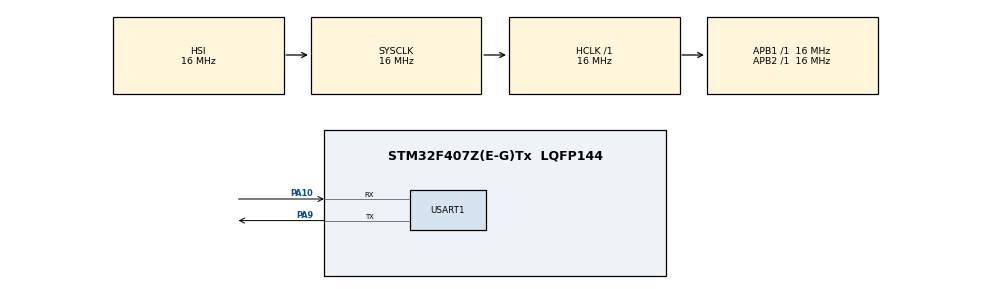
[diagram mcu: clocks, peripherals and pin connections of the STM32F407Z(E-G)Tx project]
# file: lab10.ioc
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Mcu.Family=STM32F4
Mcu.Name=STM32F407Z(E-G)Tx
Mcu.Package=LQFP144
NVIC.PriorityGroup=NVIC_PRIORITYGROUP_4
PA10.Mode=Asynchronous
PA10.Signal=USART1_RX
PA9.Mode=Asynchronous
PA9.Signal=USART1_TX
ProjectManager.HeapSize=0x200
ProjectManager.StackSize=0x400
ProjectManager.TargetToolchain=STM32CubeIDE
RCC.AHBFreq_Value=16000000
RCC.APB1Freq_Value=16000000
RCC.APB2Freq_Value=16000000
RCC.CortexFreq_Value=16000000
RCC.HSE_VALUE=25000000
RCC.HSI_VALUE=16000000
RCC.LSE_VALUE=32768
RCC.SYSCLKFreq_VALUE=16000000
RCC.VCOOutputFreq_Value=192000000
USART1.VirtualMode=VM_ASYNC
board=custom

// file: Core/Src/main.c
/* USER CODE BEGIN Header */
/**
  ******************************************************************************
  * @file           : main.c
  * @brief          : Main program body
  ******************************************************************************
  * @attention
  *
  * <h2><center>&copy; Copyright (c) 2022 STMicroelectronics.
  * All rights reserved.</center></h2>
  *
  * This software component is licensed by ST under BSD 3-Clause license,
  * the "License"; You may not use this file except in compliance with the
  * License. You may obtain a copy of the License at:
  *                        opensource.org/licenses/BSD-3-Clause
  *
  ******************************************************************************
  */
/* USER CODE END Header */
#include "main.h"

/* USER CODE BEGIN Includes */
#include "string.h"
#include "stdio.h"
/* USER CODE END Includes */

UART_HandleTypeDef huart1;

/* USER CODE BEGIN PV */
uint32_t SIZE_ONE_SECTOR = 0x4000;		// 16KB
uint32_t ADDR_FLASH_SECTOR = 0x0800C000; 	// address of 3rd sector
uint32_t val_000 = 0x01234567;
/* USER CODE END PV */

void SystemClock_Config(void);
static void MX_GPIO_Init(void);
static void MX_USART1_UART_Init(void);
/* USER CODE BEGIN PFP */
void flash_erase_one_sector(uint8_t flash_sector);
void flash_write_uint32(uint32_t, uint32_t);
uint32_t flash_read_uint32(uint32_t);
/* USER CODE END PFP */

int main(void)
{

  /* MCU Configuration--------------------------------------------------------*/

  /* Reset of all peripherals, Initializes the Flash interface and the Systick. */
  HAL_Init();

  /* USER CODE BEGIN Init */
  HAL_Delay(2000);
  /* USER CODE END Init */

  /* Configure the system clock */
  SystemClock_Config();

  /* Initialize all configured peripherals */
  MX_GPIO_Init();
  MX_USART1_UART_Init();
  /* USER CODE BEGIN 2 */
  flash_erase_one_sector(FLASH_SECTOR_3);
  flash_write_uint32(ADDR_FLASH_SECTOR, val_000);
  /* USER CODE END 2 */

  /* Infinite loop */
  while (1)
  {

  }
}

void SystemClock_Config(void)
{
  RCC_OscInitTypeDef RCC_OscInitStruct = {0};
  RCC_ClkInitTypeDef RCC_ClkInitStruct = {0};

  /** Configure the main internal regulator output voltage
  */
  __HAL_RCC_PWR_CLK_ENABLE();
  __HAL_PWR_VOLTAGESCALING_CONFIG(PWR_REGULATOR_VOLTAGE_SCALE1);
  /** Initializes the RCC Oscillators according to the specified parameters
  * in the RCC_OscInitTypeDef structure.
  */
  RCC_OscInitStruct.OscillatorType = RCC_OSCILLATORTYPE_HSI;
  RCC_OscInitStruct.HSIState = RCC_HSI_ON;
  RCC_OscInitStruct.HSICalibrationValue = RCC_HSICALIBRATION_DEFAULT;
  RCC_OscInitStruct.PLL.PLLState = RCC_PLL_NONE;
  if (HAL_RCC_OscConfig(&RCC_OscInitStruct) != HAL_OK)
  {
    Error_Handler();
  }
  /** Initializes the CPU, AHB and APB buses clocks
  */
  RCC_ClkInitStruct.ClockType = RCC_CLOCKTYPE_HCLK|RCC_CLOCKTYPE_SYSCLK
                              |RCC_CLOCKTYPE_PCLK1|RCC_CLOCKTYPE_PCLK2;
  RCC_ClkInitStruct.SYSCLKSource = RCC_SYSCLKSOURCE_HSI;
  RCC_ClkInitStruct.AHBCLKDivider = RCC_SYSCLK_DIV1;
  RCC_ClkInitStruct.APB1CLKDivider = RCC_HCLK_DIV1;
  RCC_ClkInitStruct.APB2CLKDivider = RCC_HCLK_DIV1;

  if (HAL_RCC_ClockConfig(&RCC_ClkInitStruct, FLASH_LATENCY_0) != HAL_OK)
  {
    Error_Handler();
  }
}

static void MX_USART1_UART_Init(void)
{

  huart1.Instance = USART1;
  huart1.Init.BaudRate = 115200;
  huart1.Init.WordLength = UART_WORDLENGTH_8B;
  huart1.Init.StopBits = UART_STOPBITS_1;
  huart1.Init.Parity = UART_PARITY_NONE;
  huart1.Init.Mode = UART_MODE_TX_RX;
  huart1.Init.HwFlowCtl = UART_HWCONTROL_NONE;
  huart1.Init.OverSampling = UART_OVERSAMPLING_16;
  if (HAL_UART_Init(&huart1) != HAL_OK)
  {
    Error_Handler();
  }

}

static void MX_GPIO_Init(void)
{

  /* GPIO Ports Clock Enable */
  __HAL_RCC_GPIOA_CLK_ENABLE();

}

/* USER CODE BEGIN 4 */
void flash_erase_one_sector(uint8_t flash_sector)
{
	FLASH_EraseInitTypeDef EraseInitStruct; // структура для очищення флеша

	EraseInitStruct.TypeErase = FLASH_TYPEERASE_SECTORS;
	EraseInitStruct.Banks = FLASH_BANK_1;
	EraseInitStruct.Sector = flash_sector;
	EraseInitStruct.NbSectors = 1;
	EraseInitStruct.VoltageRange = FLASH_VOLTAGE_RANGE_3;

	uint32_t sector_error = 0; // змінна в яку запишеться адреса сторінки, при невдалому очищенні

	char str[64] = { 0, };

	//////// ОЧИЩЕННЯ Flash-пам'яті ////////
	HAL_FLASH_Unlock(); // розблокування Flash-пам'яті

	if (HAL_FLASHEx_Erase(&EraseInitStruct, &sector_error) != HAL_OK)
	{
		// сталась помилка при очищенні сторінки
		uint32_t er = HAL_FLASH_GetError();
		snprintf(str, 64, "Error Flash_Erase(): %lu\n\r", er);
		HAL_UART_Transmit(&huart1, (uint8_t*) str, strlen(str), 100);
		while (1)
		{
		}
	}

	// очищення сторінки виконане успішно
	snprintf(str, 64, "Erase Flash sector %d OK\n\r", flash_sector);
	HAL_UART_Transmit(&huart1, (uint8_t*) str, strlen(str), 100);

	HAL_FLASH_Lock(); // заблокування Flash-пам'яті
}

void flash_write_uint32(uint32_t sector_address, uint32_t val)
{
	char str[64] = { 0, };

	///////////// ЗАПИС у Flash-пам'ять ///////////////
	HAL_FLASH_Unlock(); // розблокування Flash-пам'яті

	if (HAL_FLASH_Program(FLASH_TYPEPROGRAM_WORD, sector_address, val) != HAL_OK)
	{
		uint32_t er = HAL_FLASH_GetError();
		snprintf(str, 64, "Error Flash_Write(): %lu\n\r", er);
		HAL_UART_Transmit(&huart1, (uint8_t*) str, strlen(str), 100);
		while (1)
		{
		}
	}

	snprintf(str, 64, "Write 32 bits (Hex: 0x%08lX) to address 0x%08lX OK\n\r", val, sector_address);
	HAL_UART_Transmit(&huart1, (uint8_t*) str, strlen(str), 100);

	HAL_FLASH_Lock(); // заблокування Flash-пам'яті
}

uint32_t flash_read_uint32(uint32_t MYADDR)
{
	char str[64] = { 0, };

	/////////////// ЧИТАЄМО Flash-пам'ять ///////////////////
	uint32_t dig32 = *(uint32_t*) MYADDR; // читання числа за його адресою

	snprintf(str, 64, "Read 32 bits (Dec: %lu \tHex: 0x%08lX)", dig32, dig32);
	HAL_UART_Transmit(&huart1, (uint8_t*) str, strlen(str), 100);
	snprintf(str, 64, " from address 0x%08lX \n\r", MYADDR);
	HAL_UART_Transmit(&huart1, (uint8_t*) str, strlen(str), 100);

	return dig32;
}

/* USER CODE END 4 */

void Error_Handler(void)
{
  __disable_irq();
  while (1)
  {
  }
}

/************************ (C) COPYRIGHT STMicroelectronics *****END OF FILE****/
